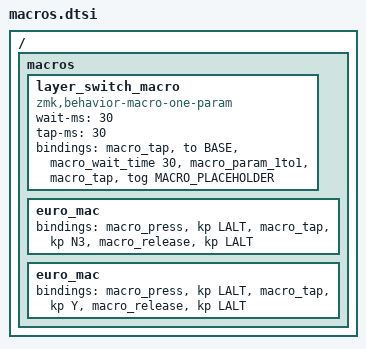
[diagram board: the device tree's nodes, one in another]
#include "layers_definitions.dtsi"

/ {
	macros {/// this approach doesn't work.k.
		layer_switch_macro: layer_switch_macro {
			compatible = "zmk,behavior-macro-one-param";
			#binding-cells = <1>;
			wait-ms = <30>;// Add a small delay to ensure proper layer switching
			tap-ms = <30>;// Add a small delay between taps
			bindings
			= <&macro_tap &to BASE>// First force switch to base layer
			, <&macro_wait_time 30>// Wait a moment for the layer switch to complete
			, <&macro_param_1to1>// Load parameter
			, <&macro_tap &tog MACRO_PLACEHOLDER>// Toggle to lock the target layer
			;
		};
		
		euro_mac: euro_mac {
			#binding-cells = <0>;
			bindings
			= <&macro_press &kp LALT>
			, <&macro_press &kp LSFT>
			, <&macro_tap &kp N2>
			, <&macro_release &kp LSFT>
			, <&macro_release &kp LALT>
			;
		};
		
		euro_mac: euro_mac {
			#binding-cells = <0>;
			bindings
			= <&macro_press &kp LALT>
			, <&macro_tap &kp N3>
			, <&macro_release &kp LALT>
			;
		};
		
		euro_mac: euro_mac {
			#binding-cells = <0>;
			bindings
			= <&macro_press &kp LALT>
			, <&macro_tap &kp Y>
			, <&macro_release &kp LALT>
			;
		};
	};
};
